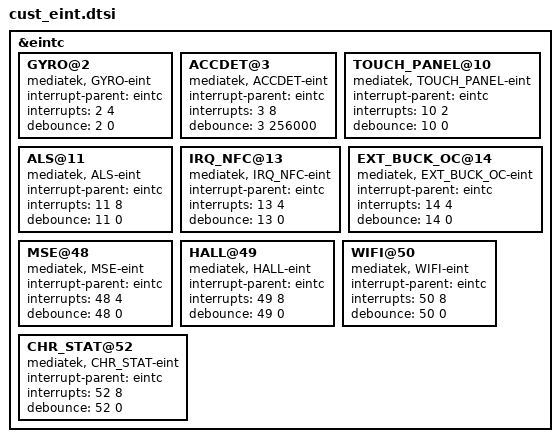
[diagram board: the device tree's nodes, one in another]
/*
 * Generated by MTK SP DrvGen Version 03.13.6 for MT6752. Copyright MediaTek Inc. (C) 2013.
 * Tue Jun 21 01:59:22 2016
 * Do Not Modify the File.
 */

/*************************
 * EINT DTSI File
*************************/

&eintc {
	GYRO@2 {
		compatible = "mediatek, GYRO-eint";
		interrupt-parent = <&eintc>;
		interrupts = <2 4>;
		debounce = <2 0>;
	};

	ACCDET@3 {
		compatible = "mediatek, ACCDET-eint";
		interrupt-parent = <&eintc>;
		interrupts = <3 8>;
		debounce = <3 256000>;
	};

	TOUCH_PANEL@10 {
		compatible = "mediatek, TOUCH_PANEL-eint";
		interrupt-parent = <&eintc>;
		interrupts = <10 2>;
		debounce = <10 0>;
	};

	ALS@11 {
		compatible = "mediatek, ALS-eint";
		interrupt-parent = <&eintc>;
		interrupts = <11 8>;
		debounce = <11 0>;
	};

	IRQ_NFC@13 {
		compatible = "mediatek, IRQ_NFC-eint";
		interrupt-parent = <&eintc>;
		interrupts = <13 4>;
		debounce = <13 0>;
	};

	EXT_BUCK_OC@14 {
		compatible = "mediatek, EXT_BUCK_OC-eint";
		interrupt-parent = <&eintc>;
		interrupts = <14 4>;
		debounce = <14 0>;
	};

	MSE@48 {
		compatible = "mediatek, MSE-eint";
		interrupt-parent = <&eintc>;
		interrupts = <48 4>;
		debounce = <48 0>;
	};

	HALL@49 {
		compatible = "mediatek, HALL-eint";
		interrupt-parent = <&eintc>;
		interrupts = <49 8>;
		debounce = <49 0>;
	};

	WIFI@50 {
		compatible = "mediatek, WIFI-eint";
		interrupt-parent = <&eintc>;
		interrupts = <50 8>;
		debounce = <50 0>;
	};

	CHR_STAT@52 {
		compatible = "mediatek, CHR_STAT-eint";
		interrupt-parent = <&eintc>;
		interrupts = <52 8>;
		debounce = <52 0>;
	};

};
